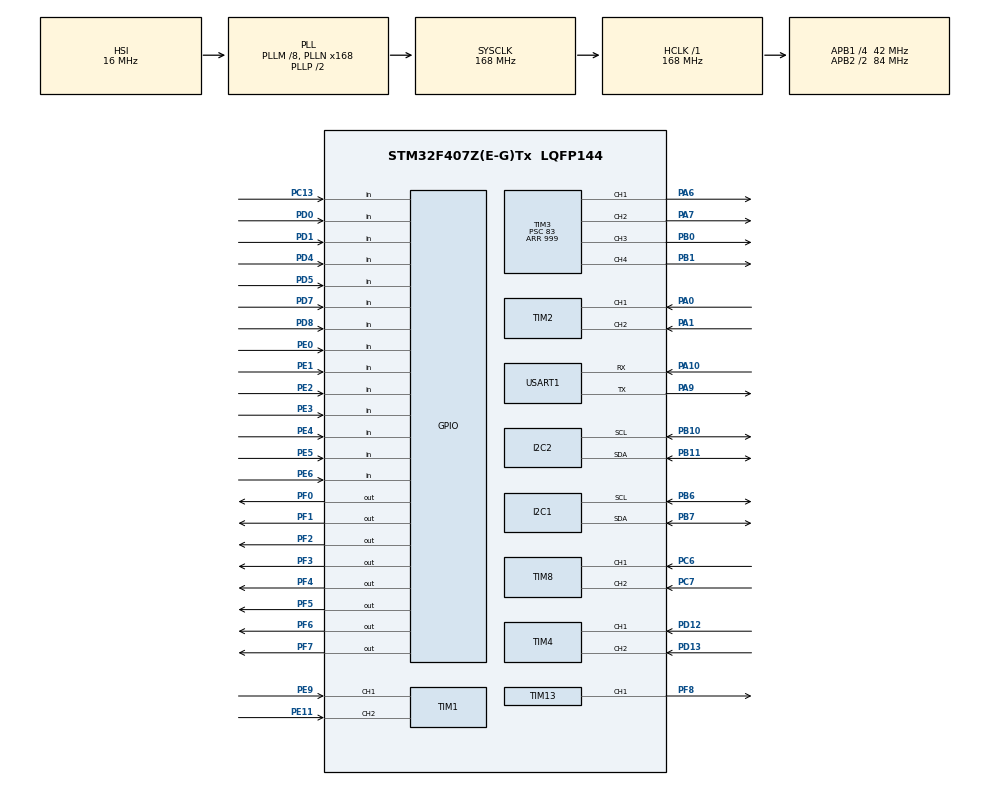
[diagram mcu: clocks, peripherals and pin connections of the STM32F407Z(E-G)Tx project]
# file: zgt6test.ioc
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FREERTOS.Tasks01=defaultTask,24,128,StartDefaultTask,Default,NULL,Dynamic,NULL,NULL;motor_task,24,512,MotorTask,As weak,NULL,Dynamic,NULL,NULL
I2C1.I2C_Mode=I2C_Fast
Mcu.Family=STM32F4
Mcu.Name=STM32F407Z(E-G)Tx
Mcu.Package=LQFP144
NVIC.PriorityGroup=NVIC_PRIORITYGROUP_4
NVIC.USART1_IRQn=true\:5\:0\:false\:false\:true\:true\:true\:true\:true
PA0-WKUP.Signal=S_TIM2_CH1_ETR
PA1.Signal=S_TIM2_CH2
PA10.Mode=Asynchronous
PA10.Signal=USART1_RX
PA13.Mode=Serial_Wire
PA13.Signal=SYS_JTMS-SWDIO
PA14.Mode=Serial_Wire
PA14.Signal=SYS_JTCK-SWCLK
PA6.Signal=S_TIM3_CH1
PA7.Signal=S_TIM3_CH2
PA9.Mode=Asynchronous
PA9.Signal=USART1_TX
PB0.Signal=S_TIM3_CH3
PB1.Signal=S_TIM3_CH4
PB10.Mode=I2C
PB10.Signal=I2C2_SCL
PB11.Mode=I2C
PB11.Signal=I2C2_SDA
PB6.Mode=I2C
PB6.Signal=I2C1_SCL
PB7.Mode=I2C
PB7.Signal=I2C1_SDA
PC13-ANTI_TAMP.GPIO_PuPd=GPIO_NOPULL
PC13-ANTI_TAMP.Signal=GPIO_Input
PC14-OSC32_IN.Mode=LSE-External-Oscillator
PC14-OSC32_IN.Signal=RCC_OSC32_IN
PC15-OSC32_OUT.Mode=LSE-External-Oscillator
PC15-OSC32_OUT.Signal=RCC_OSC32_OUT
PC6.Signal=S_TIM8_CH1
PC7.Signal=S_TIM8_CH2
PD0.GPIO_PuPd=GPIO_PULLUP
PD0.Signal=GPIO_Input
PD1.GPIO_PuPd=GPIO_PULLUP
PD1.Signal=GPIO_Input
PD12.Signal=S_TIM4_CH1
PD13.Signal=S_TIM4_CH2
PD4.GPIO_PuPd=GPIO_PULLUP
PD4.Signal=GPIO_Input
PD5.GPIO_PuPd=GPIO_PULLUP
PD5.Signal=GPIO_Input
PD7.GPIO_PuPd=GPIO_PULLUP
PD7.Signal=GPIO_Input
PD8.GPIO_PuPd=GPIO_PULLUP
PD8.Signal=GPIO_Input
PE0.Signal=GPIO_Input
PE1.Signal=GPIO_Input
PE11.Signal=S_TIM1_CH2
PE2.Signal=GPIO_Input
PE3.Signal=GPIO_Input
PE4.Signal=GPIO_Input
PE5.Signal=GPIO_Input
PE6.Signal=GPIO_Input
PE9.Signal=S_TIM1_CH1
PF0.Signal=GPIO_Output
PF1.Signal=GPIO_Output
PF2.Signal=GPIO_Output
PF3.Signal=GPIO_Output
PF4.Signal=GPIO_Output
PF5.Signal=GPIO_Output
PF6.Signal=GPIO_Output
PF7.Signal=GPIO_Output
PF8.Signal=S_TIM13_CH1
PH0-OSC_IN.Mode=HSE-External-Oscillator
PH0-OSC_IN.Signal=RCC_OSC_IN
PH1-OSC_OUT.Mode=HSE-External-Oscillator
PH1-OSC_OUT.Signal=RCC_OSC_OUT
ProjectManager.HeapSize=0x200
ProjectManager.StackSize=0x400
ProjectManager.TargetToolchain=CMake
RCC.48MHZClocksFreq_Value=84000000
RCC.AHBFreq_Value=168000000
RCC.APB1CLKDivider=RCC_HCLK_DIV4
RCC.APB1Freq_Value=42000000
RCC.APB1TimFreq_Value=84000000
RCC.APB2CLKDivider=RCC_HCLK_DIV2
RCC.APB2Freq_Value=84000000
RCC.APB2TimFreq_Value=168000000
RCC.CortexFreq_Value=168000000
RCC.HCLKFreq_Value=168000000
RCC.HSE_VALUE=25000000
RCC.HSI_VALUE=16000000
RCC.PLLM=8
RCC.PLLN=168
RCC.SYSCLKFreq_VALUE=168000000
RCC.SYSCLKSource=RCC_SYSCLKSOURCE_PLLCLK
RCC.VCOOutputFreq_Value=336000000
SH.S_TIM13_CH1.0=TIM13_CH1,PWM Generation1 CH1
SH.S_TIM1_CH1.0=TIM1_CH1,Encoder_Interface
SH.S_TIM1_CH2.0=TIM1_CH2,Encoder_Interface
SH.S_TIM2_CH1_ETR.0=TIM2_CH1,Encoder_Interface
SH.S_TIM2_CH2.0=TIM2_CH2,Encoder_Interface
SH.S_TIM3_CH1.0=TIM3_CH1,PWM Generation1 CH1
SH.S_TIM3_CH2.0=TIM3_CH2,PWM Generation2 CH2
SH.S_TIM3_CH3.0=TIM3_CH3,PWM Generation3 CH3
SH.S_TIM3_CH4.0=TIM3_CH4,PWM Generation4 CH4
SH.S_TIM4_CH1.0=TIM4_CH1,Encoder_Interface
SH.S_TIM4_CH2.0=TIM4_CH2,Encoder_Interface
SH.S_TIM8_CH1.0=TIM8_CH1,Encoder_Interface
SH.S_TIM8_CH2.0=TIM8_CH2,Encoder_Interface
TIM1.EncoderMode=TIM_ENCODERMODE_TI12
TIM13.Channel=TIM_CHANNEL_1
TIM2.EncoderMode=TIM_ENCODERMODE_TI12
TIM3.Channel-PWM\ Generation1\ CH1=TIM_CHANNEL_1
TIM3.Channel-PWM\ Generation2\ CH2=TIM_CHANNEL_2
TIM3.Channel-PWM\ Generation3\ CH3=TIM_CHANNEL_3
TIM3.Channel-PWM\ Generation4\ CH4=TIM_CHANNEL_4
TIM3.Period=999
TIM3.Prescaler=83
TIM4.EncoderMode=TIM_ENCODERMODE_TI12
TIM8.EncoderMode=TIM_ENCODERMODE_TI12
USART1.VirtualMode=VM_ASYNC
VP_FREERTOS_VS_CMSIS_V2.Mode=CMSIS_V2
VP_TIM13_VS_ClockSourceINT.Mode=Enable_Timer
VP_TIM3_VS_ClockSourceINT.Mode=Internal
board=custom

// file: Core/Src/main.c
/* USER CODE BEGIN Header */
/**
  ******************************************************************************
  * @file           : main.c
  * @brief          : Main program body
  ******************************************************************************
  * @attention
  *
  * Copyright (c) 2025 STMicroelectronics.
  * All rights reserved.
  *
  * This software is licensed under terms that can be found in the LICENSE file
  * in the root directory of this software component.
  * If no LICENSE file comes with this software, it is provided AS-IS.
  *
  ******************************************************************************
  */
/* USER CODE END Header */
#include "main.h"
#include "cmsis_os.h"
#include "i2c.h"
#include "tim.h"
#include "usart.h"
#include "gpio.h"

void SystemClock_Config(void);
void MX_FREERTOS_Init(void);

int main(void)
{

  /* MCU Configuration--------------------------------------------------------*/

  /* Reset of all peripherals, Initializes the Flash interface and the Systick. */
  HAL_Init();

  /* Configure the system clock */
  SystemClock_Config();

  /* Initialize all configured peripherals */
  MX_GPIO_Init();
  MX_USART1_UART_Init();
  MX_TIM3_Init();
  MX_TIM2_Init();
  MX_I2C1_Init();
  MX_TIM1_Init();
  MX_TIM4_Init();
  MX_TIM8_Init();
  MX_TIM13_Init();
  MX_I2C2_Init();

  /* Init scheduler */
  osKernelInitialize();

  /* Call init function for freertos objects (in cmsis_os2.c) */
  MX_FREERTOS_Init();

  /* Start scheduler */
  osKernelStart();

  /* We should never get here as control is now taken by the scheduler */

  /* Infinite loop */
  /* USER CODE BEGIN WHILE */
  while (1)
  {
    // HAL_GPIO_TogglePin(GPIOF, GPIO_PIN_0);
    // HAL_Delay(1000);
    // printf("%dHello World\n",i++);
    // HAL_Delay(1000);
    /* USER CODE END WHILE */

  }
}

void SystemClock_Config(void)
{
  RCC_OscInitTypeDef RCC_OscInitStruct = {0};
  RCC_ClkInitTypeDef RCC_ClkInitStruct = {0};

  /** Configure the main internal regulator output voltage
  */
  __HAL_RCC_PWR_CLK_ENABLE();
  __HAL_PWR_VOLTAGESCALING_CONFIG(PWR_REGULATOR_VOLTAGE_SCALE1);

  /** Initializes the RCC Oscillators according to the specified parameters
  * in the RCC_OscInitTypeDef structure.
  */
  RCC_OscInitStruct.OscillatorType = RCC_OSCILLATORTYPE_HSI;
  RCC_OscInitStruct.HSIState = RCC_HSI_ON;
  RCC_OscInitStruct.HSICalibrationValue = RCC_HSICALIBRATION_DEFAULT;
  RCC_OscInitStruct.PLL.PLLState = RCC_PLL_ON;
  RCC_OscInitStruct.PLL.PLLSource = RCC_PLLSOURCE_HSI;
  RCC_OscInitStruct.PLL.PLLM = 8;
  RCC_OscInitStruct.PLL.PLLN = 168;
  RCC_OscInitStruct.PLL.PLLP = RCC_PLLP_DIV2;
  RCC_OscInitStruct.PLL.PLLQ = 4;
  if (HAL_RCC_OscConfig(&RCC_OscInitStruct) != HAL_OK)
  {
    Error_Handler();
  }

  /** Initializes the CPU, AHB and APB buses clocks
  */
  RCC_ClkInitStruct.ClockType = RCC_CLOCKTYPE_HCLK|RCC_CLOCKTYPE_SYSCLK
                              |RCC_CLOCKTYPE_PCLK1|RCC_CLOCKTYPE_PCLK2;
  RCC_ClkInitStruct.SYSCLKSource = RCC_SYSCLKSOURCE_PLLCLK;
  RCC_ClkInitStruct.AHBCLKDivider = RCC_SYSCLK_DIV1;
  RCC_ClkInitStruct.APB1CLKDivider = RCC_HCLK_DIV4;
  RCC_ClkInitStruct.APB2CLKDivider = RCC_HCLK_DIV2;

  if (HAL_RCC_ClockConfig(&RCC_ClkInitStruct, FLASH_LATENCY_5) != HAL_OK)
  {
    Error_Handler();
  }
}

void Error_Handler(void)
{
  __disable_irq();
  while (1)
  {
  }
}

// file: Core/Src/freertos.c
/* USER CODE BEGIN Header */
/**
  ******************************************************************************
  * File Name          : freertos.c
  * Description        : Code for freertos applications
  ******************************************************************************
  * @attention
  *
  * Copyright (c) 2025 STMicroelectronics.
  * All rights reserved.
  *
  * This software is licensed under terms that can be found in the LICENSE file
  * in the root directory of this software component.
  * If no LICENSE file comes with this software, it is provided AS-IS.
  *
  ******************************************************************************
  */
/* USER CODE END Header */

#include "FreeRTOS.h"
#include "task.h"
#include "main.h"
#include "cmsis_os.h"

/* USER CODE BEGIN Includes */
#include <stdio.h>

#include "bsp_encoder.h"
#include "bsp_imu_mpu6050.h"
#include "i2c.h"
#include "task_motor.h"
#include "tim.h"

/* USER CODE END Includes */

/* Definitions for defaultTask */
osThreadId_t defaultTaskHandle;
const osThreadAttr_t defaultTask_attributes = {
  .name = "defaultTask",
  .stack_size = 128 * 4,
  .priority = (osPriority_t) osPriorityNormal,
};
/* Definitions for motor_task */
osThreadId_t motor_taskHandle;
const osThreadAttr_t motor_task_attributes = {
  .name = "motor_task",
  .stack_size = 512 * 4,
  .priority = (osPriority_t) osPriorityNormal,
};

void StartDefaultTask(void *argument);
void MotorTask(void *argument);

void MX_FREERTOS_Init(void); /* (MISRA C 2004 rule 8.1) */

void MX_FREERTOS_Init(void) {

  /* Create the thread(s) */
  /* creation of defaultTask */
  defaultTaskHandle = osThreadNew(StartDefaultTask, NULL, &defaultTask_attributes);

  /* creation of motor_task */
  motor_taskHandle = osThreadNew(MotorTask, NULL, &motor_task_attributes);

}

void StartDefaultTask(void *argument)
{
  /* USER CODE BEGIN StartDefaultTask */
  // Encoder_HandleTypeDef encoder1 = {
  //   .htim = &htim2 // 例如用TIM3
  // };
  //
  // Encoder_Init(&encoder1);

//
//   MPU6050_HandleTypeDef mpu = {
//     .hi2c = &hi2c1, // CubeMX生成的I2C句柄
//     .addr = 0       // 自动填，不用管
// };
//   uint8_t err = MPU6050_Init(&mpu);
//   if (err != 0) {
//     printf("MPU6050初始化失败，错误码：%d\r\n", err);
//   }
//   if (MPU6050_Init(&mpu) != 0) {
//     printf("MPU6050初始化失败！\r\n");
//     return;
//   }
  /* Infinite loop */
  for(;;)
  {
    // Encoder_Update(&encoder1);  // 每循环/定时周期调用一次
    // int32_t total = Encoder_GetCount(&encoder1);
    // int16_t speed = Encoder_GetSpeed(&encoder1);
    //
    // // 打印或用于PID
    // printf("%d\r\n", speed);

    // float ax=0, ay=0, az=0, gx=0, gy=0, gz=0;
    // if (MPU6050_ReadRaw(&mpu) == 0) {
    //   MPU6050_GetAccelGyro(&mpu, &ax, &ay, &az, &gx, &gy, &gz);
    //   printf("g: %.3f %.3f %.3f dps: %.3f %.3f %.3f t:%.2f\r\n",
    //       ax, ay, az, gx, gy, gz, mpu.temp_deg);
    // } else {
    //   printf("读取MPU6050失败！\r\n");
    // }

    osDelay(10);
  }
  /* USER CODE END StartDefaultTask */
}

__weak void MotorTask(void *argument)
{
  for(;;)
  {
    osDelay(1);
  }
}
